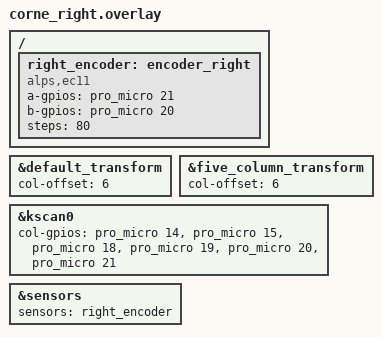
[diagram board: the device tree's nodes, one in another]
/*
 * Copyright (c) 2020 Pete Johanson
 *
 * SPDX-License-Identifier: MIT
 */

#include "corne.dtsi"

&default_transform {
    col-offset = <6>;
};

&five_column_transform {
    col-offset = <6>;
};

&kscan0 {
    col-gpios
        = <&pro_micro 14 GPIO_ACTIVE_HIGH>
        , <&pro_micro 15 GPIO_ACTIVE_HIGH>
        , <&pro_micro 18 GPIO_ACTIVE_HIGH>
        , <&pro_micro 19 GPIO_ACTIVE_HIGH>
        , <&pro_micro 20 GPIO_ACTIVE_HIGH>
        , <&pro_micro 21 GPIO_ACTIVE_HIGH>
        ;
};
/ {
    right_encoder: encoder_right {
        compatible = "alps,ec11";
        // Укажите пины для правой половинки
        a-gpios = <&pro_micro 21 (GPIO_ACTIVE_HIGH | GPIO_PULL_UP)>;
        b-gpios = <&pro_micro 20 (GPIO_ACTIVE_HIGH | GPIO_PULL_UP)>;
        steps = <80>;
    };
};

&sensors {
    status = "okay";
    sensors = <&right_encoder>;
};
// vim: filetype=dts fdm=marker:
